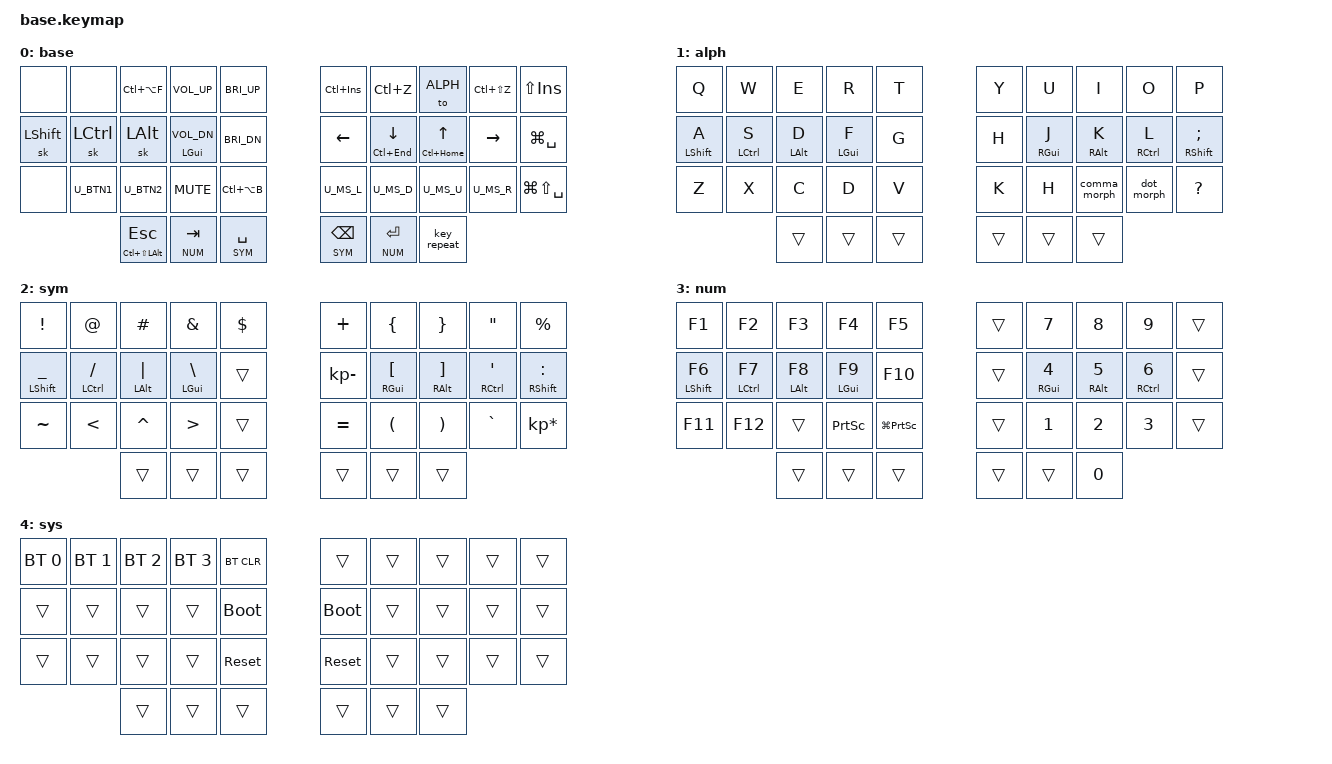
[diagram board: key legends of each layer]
#include <behaviors.dtsi>
#include <behaviors/num_word.dtsi> // Requires auto-layer module.
#include <dt-bindings/zmk/keys.h>
#include <dt-bindings/zmk/bt.h>
#define _BT_SEL_KEYS_ &bt BT_SEL 0 &bt BT_SEL 1 &bt BT_SEL 2 &bt BT_SEL 3 &bt BT_CLR

// #include "../zmk-nodefree-config/helper.h"
// #include "../zmk-nodefree-config/international_chars/german.dtsi"

/* Keymap */
#define DEF 0
#define ALPH 1
#define SYM 2
#define NUM 3
#define SYS 4

#include "combos.dtsi"  // requires layer aliases
// #include "mouse.dtsi"

#define XXX &none
#define ___ &trans

/* Global defaults */

#define QUICK_TAP_MS 175

&sk {
  release-after-ms = <900>;
  quick-release;
};

&sl { // Allow sticky mods to chord across sticky layers.
  ignore-modifiers;
};

&lt {
  flavor = "balanced";
  tapping-term-ms = <200>;
  quick-tap-ms = <QUICK_TAP_MS>;
};

/* Homerow mods */
#define KEYS_L LT0 LT1 LT2 LT3 LT4 LM0 LM1 LM2 LM3 LM4 LB0 LB1 LB2 LB3 LB4  // left hand
#define KEYS_R RT0 RT1 RT2 RT3 RT4 RM0 RM1 RM2 RM3 RM4 RB0 RB1 RB2 RB3 RB4  // right hand
#define THUMBS LH2 LH1 LH0 RH0 RH1 RH2                                      // thumbs

#define MAKE_HRM(NAME, HOLD, TAP, TRIGGER_POS)                                 \
  ZMK_HOLD_TAP(NAME, bindings = <HOLD>, <TAP>; flavor = "balanced";            \
               tapping-term-ms = <280>; quick-tap-ms = <QUICK_TAP_MS>;         \
               require-prior-idle-ms = <150>; hold-trigger-on-release;         \
               hold-trigger-key-positions = <TRIGGER_POS>;)

/* Nav cluster */
#define NAV_UP    &mt LC(HOME) UP      // tap: up    | long-tap: beginning of document
#define NAV_DOWN  &mt LC(END)  DOWN    // tap: down  | long-tap: end       of document

// mask CTRL when holding left/right to avoid accidental jumps to beginning/end of document
#define MASK_MODS(NAME, MODS, BINDING) \
    ZMK_BEHAVIOR(NAME, mod_morph, \
        bindings = <BINDING>, <BINDING>; \
        mods = <MODS>; \
    )

/* Custom behaviors */

// Alt+Tab swapper, requires tri-state module.
ZMK_TRI_STATE(swapper, bindings = <&kt LALT>, <&kp TAB>, <&kt LALT>;
              ignored-key-positions = <LT2>;)


// Sticky layer + sticky shift (workaround for issue #1421)
ZMK_BEHAVIOR(sls, sticky_key,
    release-after-ms = <1000>;
    bindings = <&sym_shift>;
    ignore-modifiers;
)
ZMK_BEHAVIOR(sym_shift, macro,
    wait-ms = <0>;
    tap-ms = <1>;
    bindings = <&macro_press &mo SYM &kp LSHFT>
             , <&macro_pause_for_release>
             , <&macro_release &mo SYM &kp LSHFT>;
)

// Tap: comma | Shift + tap: semicolon | Ctrl + shift + tap: <.
SIMPLE_MORPH(comma_morph, SFT, &kp COMMA, &comma_inner_morph)
SIMPLE_MORPH(comma_inner_morph, CTL, &kp SEMICOLON, &kp LESS_THAN)

// Tap: dot | Shift + tap: colon | Ctrl + shift + tap: >.
SIMPLE_MORPH(dot_morph, SFT, &kp DOT, &dot_inner_morph)
SIMPLE_MORPH(dot_inner_morph, CTL, &kp COLON, &kp GREATER_THAN)

// Tap: qmark | Shift + tap: excl.
SIMPLE_MORPH(qexcl, SFT, &kp QMARK, &kp EXCL)

// misc aliases
#define SAVE_PRNT   &kp LG(PSCRN)             // Save printscreen
#define CPY         &kp LC(INS)               // Copy selection
#define PST         &kp LS(INS)               // Paste selection
#define UND         &kp LC(Z)                 // undo
#define RED         &kp LC(LS(Z))             // redo
#define ESC_MEH     &hmr LC(LS(LALT)) ESC     // Escape | Hold: MEH
#define FINDER      &kp LG(SPACE)             // Open Finder

/* Keymap */

ZMK_CONDITIONAL_LAYER(NUM SYM, SYS)  // NUM + SYM --> SYS

/* vim: set ft=c tw=146: */
ZMK_LAYER(base,
//╭─────────────┬─────────────┬──────────────┬───────────────────┬──────────────╮ ╭─────────────┬─────────────┬─────────────┬─────────────┬──────────────────╮
    XXX           XXX           &kp LC(LA(F))  &kp C_VOL_UP        &kp C_BRI_UP     CPY           UND           &to ALPH      RED           PST
//├─────────────┼─────────────┼──────────────┼───────────────────┼──────────────┤ ├─────────────┼─────────────┼─────────────┼─────────────┼──────────────────┤
    &sk LSHFT     &sk LCTRL     &sk LALT       &hml LGUI C_VOL_DN  &kp C_BRI_DN     &kp LEFT      NAV_DOWN      NAV_UP        &kp RIGHT     &kp LG(SPACE)
//├─────────────┼─────────────┼──────────────┼───────────────────┼──────────────┤ ├─────────────┼─────────────┼─────────────┼─────────────┼──────────────────┤
    XXX           U_BTN1        U_BTN2         &kp C_MUTE          &kp LC(LA(B))    U_MS_L        U_MS_D        U_MS_U        U_MS_R        &kp LG(LS(SPACE))
//╰─────────────┴─────────────┼──────────────┼───────────────────┼──────────────┤ ├─────────────┼─────────────┼─────────────┼─────────────┴──────────────────╯
                                ESC_MEH        &lt NUM TAB         &lt SYM SPACE    &lt SYM BSPC  &lt NUM RET   &key_repeat
//                            ╰──────────────┴───────────────────┴──────────────╯ ╰─────────────┴─────────────┴─────────────╯
)

ZMK_LAYER(alph,
//╭─────────────┬─────────────┬─────────────┬─────────────┬───────────────╮ ╭─────────────┬─────────────┬─────────────┬─────────────┬─────────────────╮
    &kp Q         &kp W         &kp E         &kp R         &kp T             &kp Y         &kp U         &kp I         &kp O         &kp P
//├─────────────┼─────────────┼─────────────┼─────────────┼───────────────┤ ├─────────────┼─────────────┼─────────────┼─────────────┼─────────────────┤
    &hml LSHFT A  &hml LCTRL S  &hml LALT D   &hml LGUI F   &kp G             &kp H         &hmr RGUI J   &hmr RALT K   &hmr RCTRL L  &hmr RSHFT SEMI
//├─────────────┼─────────────┼─────────────┼─────────────┼───────────────┤ ├─────────────┼─────────────┼─────────────┼─────────────┼─────────────────┤
    &kp Z         &kp X         &kp C         &kp D         &kp V             &kp K         &kp H         &comma_morph  &dot_morph    &kp QMARK
//╰─────────────┴─────────────┼─────────────┼─────────────┼───────────────┤ ├─────────────┼─────────────┼─────────────┼─────────────┴─────────────────╯
                                ___           ___           ___               ___           ___           ___
//                            ╰─────────────┴─────────────┴───────────────╯ ╰─────────────┴─────────────┴─────────────╯
)

ZMK_LAYER(sym,
//╭──────────────────┬────────────────┬───────────────┬─────────────────┬─────────────╮ ╭─────────────┬────────────────┬────────────────┬───────────────┬─────────────────╮
    &kp EXCL           &kp AT           &kp POUND       &kp AMPS          &kp DLLR        &kp PLUS      &kp LBRC         &kp RBRC         &kp DQT         &kp PRCNT
//├──────────────────┼────────────────┼───────────────┼─────────────────┼─────────────┤ ├─────────────┼────────────────┼────────────────┼───────────────┼─────────────────┤
    &hml LSHFT UNDER   &hml LCTRL FSLH  &hml LALT PIPE  &hml LGUI BSLH    ___             &kp KP_MINUS  &hmr RGUI LBKT   &hmr RALT RBKT   &hmr RCTRL SQT  &hmr RSHFT COLON
//├──────────────────┼────────────────┼───────────────┼─────────────────┼─────────────┤ ├─────────────┼────────────────┼────────────────┼───────────────┼─────────────────┤
    &kp TILDE          &kp LT           &kp CARET       &kp GT            ___             &kp EQUAL     &kp LPAR         &kp RPAR         &kp GRAVE       &kp KP_ASTERISK
//╰──────────────────┴────────────────┼───────────────┼─────────────────┼─────────────┤ ├─────────────┼────────────────┼────────────────┼───────────────┴─────────────────╯
                                        ___             ___               ___             ___           ___              ___
//                                    ╰───────────────┴─────────────────┴─────────────╯ ╰─────────────┴────────────────┴────────────────╯
)

ZMK_LAYER(num,
//╭───────────────┬───────────────┬───────────────┬─────────────┬─────────────╮ ╭─────────────┬─────────────┬─────────────┬───────────────┬─────────────╮
    &kp F1          &kp F2          &kp F3          &kp F4        &kp F5          ___           &kp N7        &kp N8        &kp N9          ___
//├───────────────┼───────────────┼───────────────┼─────────────┼─────────────┤ ├─────────────┼─────────────┼─────────────┼───────────────┼─────────────┤
    &hml LSHFT F6   &hml LCTRL F7   &hml LALT F8    &hml LGUI F9  &kp F10         ___           &hmr RGUI N4  &hmr RALT N5  &hmr RCTRL N6   ___
//├───────────────┼───────────────┼───────────────┼─────────────┼─────────────┤ ├─────────────┼─────────────┼─────────────┼───────────────┼─────────────┤
    &kp F11         &kp F12         ___             &kp PSCRN     SAVE_PRNT       ___           &kp N1        &kp N2        &kp N3          ___
//╰───────────────┴───────────────┼───────────────┼─────────────┼─────────────┤ ├─────────────┼─────────────┼─────────────┼───────────────┴─────────────╯
                                    ___             ___           ___             ___           ___           &kp N0
//                                ╰───────────────┴─────────────┴─────────────╯ ╰─────────────┴─────────────┴─────────────╯
)

ZMK_LAYER(sys,
//╭─────────────┬─────────────┬─────────────┬─────────────┬─────────────╮ ╭─────────────┬─────────────┬─────────────┬─────────────┬─────────────╮
    &bt BT_SEL 0  &bt BT_SEL 1  &bt BT_SEL 2  &bt BT_SEL 3  &bt BT_CLR      ___           ___           ___           ___           ___
//├─────────────┼─────────────┼─────────────┼─────────────┼─────────────┤ ├─────────────┼─────────────┼─────────────┼─────────────┼─────────────┤
    ___           ___           ___           ___           &bootloader     &bootloader   ___           ___           ___           ___
//├─────────────┼─────────────┼─────────────┼─────────────┼─────────────┤ ├─────────────┼─────────────┼─────────────┼─────────────┼─────────────┤
    ___           ___           ___           ___           &sys_reset      &sys_reset    ___           ___           ___           ___
//╰─────────────┴─────────────┼─────────────┼─────────────┼─────────────┤ ├─────────────┼─────────────┼─────────────┼─────────────┴─────────────╯
                                ___           ___           ___             ___           ___           ___
//                            ╰─────────────┴─────────────┴─────────────╯ ╰─────────────┴─────────────┴─────────────╯
)

/* vim: set ft=c tw=174: */
